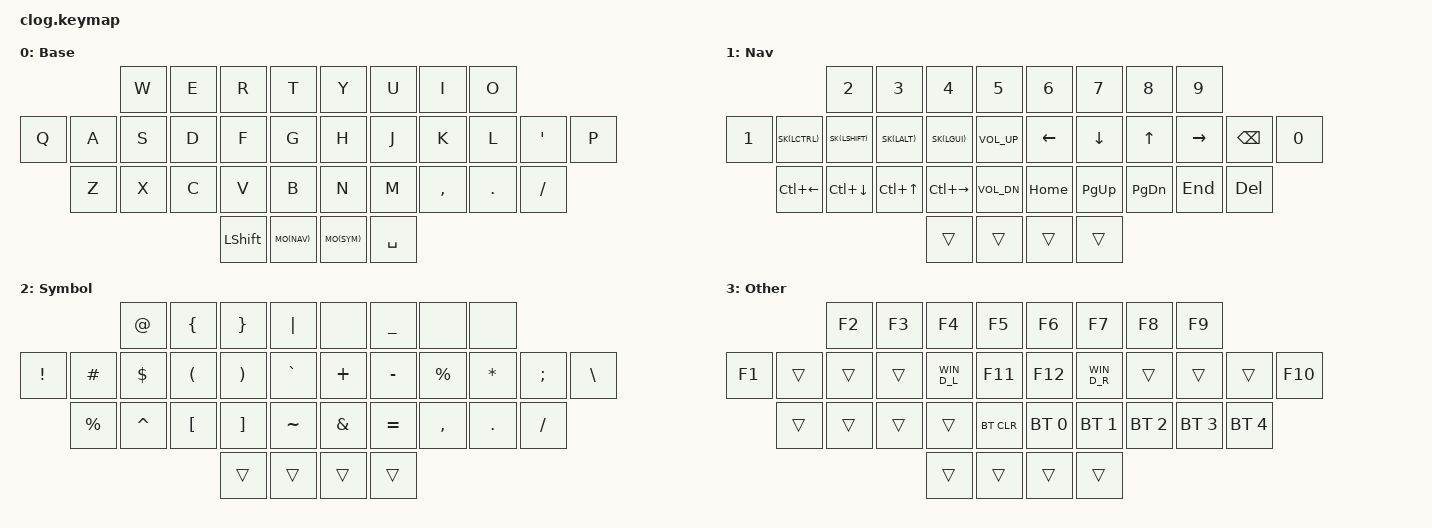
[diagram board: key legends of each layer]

/*
 * Copyright (c) 2021 The ZMK Contributors
 *
 * SPDX-License-Identifier: MIT
 */

#include <behaviors.dtsi>
#include <dt-bindings/zmk/keys.h>
#include <dt-bindings/zmk/bt.h>
#include <dt-bindings/zmk/outputs.h>

#define XXX &none
#define ___ &trans

#define WIN_D_L LC(LG(LEFT))
#define WIN_D_R LC(LG(RIGHT))

#define SK(KEY) &nk KEY KEY
#define MO(LAYER) &mo_tap LAYER F24

// Keep sticky keys active for a long time so they effectively do not time out
#define STICKY_KEY_TIMEOUT 60000

#define BASE 0
#define NAV 1
#define SYM 2
#define OTHER 3

&sk {
  release-after-ms = <STICKY_KEY_TIMEOUT>;
};

/ {
    combos {
        compatible = "zmk,combos";

/*              34-KEY POSITIONS

          ╭─────────────────╮ ╭──────────────────╮
  ╭───────╯  0   1   2   3  │ │   4   5   6   7  ╰──────╮
  │  8   9  10  11  12  13  │ │  14  15  16  17  18  19 │
  ╰───╮ 20  21  22  23  24  │ │  25  26  27  28  29 ╭───╯
      ╰──────────╮  30  31  │ │ 32  33 ╭────────────╯
                 ╰──────────╯ ╰────────╯            */


        escape {
            timeout-ms = <50>;
            key-positions = <8 12>;
            bindings = <&kp ESC>;
        };


        enter {
            timeout-ms = <50>;
            key-positions = <15 19>;
            bindings = <&kp ENTER>;
        };

        tab {
            timeout-ms = <50>;
            key-positions = <12 31>;
            bindings = <&kp TAB>;
        };

        untab {
            timeout-ms = <50>;
            key-positions = <15 32>;
            bindings = <&kp LS(TAB)>;
        };

    };

    behaviors {

      skq: sticky_key_quick_release {
        compatible = "zmk,behavior-sticky-key";
        label = "STICKY_KEY_QUICK_RELEASE";
        #binding-cells = <1>;
        bindings = <&kp>;
        quick-release;
        release-after-ms = <STICKY_KEY_TIMEOUT>;
      };

      // Use hold-tap to enable rolling sticky keys:
      // https://github.com/zmkfirmware/zmk/issues/829#issuecomment-979864774
      nk: not_so_sticky_key {
        compatible = "zmk,behavior-hold-tap";
        label = "NOT_SO_STICKY_KEY";
        #binding-cells = <2>;
        tapping_term_ms = <200>;
        flavor = "tap-preferred";
        bindings = <&kp>, <&sk>;
      };

      // A hold-tap that activates without delay (like `&mo`)
      mo_tap: mo_with_tap {
        compatible = "zmk,behavior-hold-tap";
        label = "MO_WITH_TAP";
        #binding-cells = <2>;
        tapping_term_ms = <0>;
        retro-tap;
        flavor = "hold-preferred";
        bindings = <&mo>, <&kp>;
      };

    };

    conditional_layers {
        compatible = "zmk,conditional-layers";
        tri_layer {
          if-layers = <NAV SYM>;
          then-layer= <OTHER>;
        };
    };

    keymap {
        compatible = "zmk,keymap";

        base_layer {
            label = "Base";
            bindings = <
        //                             ╭─────────────┬─────────────┬─────────────┬─────────────╮   ╭─────────────┬─────────────┬─────────────┬─────────────╮
                                         &kp W         &kp E         &kp R         &kp T             &kp Y         &kp U         &kp I         &kp O         
        // ╭─────────────┬─────────────┼─────────────┼─────────────┼─────────────┼─────────────┤   ├─────────────┼─────────────┼─────────────┼─────────────┼─────────────┬─────────────╮
             &kp Q         &kp A         &kp S         &kp D         &kp F         &kp G             &kp H         &kp J         &kp K         &kp L         &kp QUOT      &kp P         
        // ╰─────────────┼─────────────┼─────────────┼─────────────┼─────────────┼─────────────┤   ├─────────────┼─────────────┼─────────────┼─────────────┼─────────────┼─────────────╯
                           &kp Z         &kp X         &kp C         &kp V         &kp B             &kp N         &kp M         &kp COMMA     &kp DOT       &kp FSLH
        //               ╰─────────────┴─────────────┴─────────────┼─────────────┼─────────────┤   ├─────────────┼─────────────┼─────────────┴─────────────┴─────────────╯
                                                                     &kp LSHIFT    MO(NAV)           MO(SYM)       &kp SPACE     
        //                                                         ╰─────────────┴─────────────╯   ╰─────────────┴─────────────╯
            >;
        };

        nav_layer {
            label = "Nav";
            bindings = <
        //                             ╭─────────────┬─────────────┬─────────────┬─────────────╮   ╭─────────────┬─────────────┬─────────────┬─────────────╮
                                         &kp N2        &kp N3        &kp N4        &kp N5            &kp N6        &kp N7        &kp N8        &kp N9        
        // ╭─────────────┬─────────────┼─────────────┼─────────────┼─────────────┼─────────────┤   ├─────────────┼─────────────┼─────────────┼─────────────┼─────────────┬─────────────╮
             &kp N1        SK(LCTRL)     SK(LSHIFT)    SK(LALT)      SK(LGUI)      &kp C_VOL_UP      &kp LEFT      &kp DOWN      &kp UP        &kp RIGHT     &kp BSPC      &kp N0 
        // ╰─────────────┼─────────────┼─────────────┼─────────────┼─────────────┼─────────────┤   ├─────────────┼─────────────┼─────────────┼─────────────┼─────────────┼─────────────╯
                           &kp LC(LEFT)  &kp LC(DOWN)  &kp LC(UP)    &kp LC(RIGHT) &kp C_VOL_DN      &kp HOME      &kp PG_UP     &kp PG_DN     &kp END       &kp DEL
        //               ╰─────────────┴─────────────┴─────────────┼─────────────┼─────────────┤   ├─────────────┼─────────────┼─────────────┴─────────────┴─────────────╯
                                                                     ___           ___               ___           ___
        //                                                         ╰─────────────┴─────────────╯   ╰─────────────┴─────────────╯
            >;
        };

        sym_layer {
            label = "Symbol";
            bindings = <
        //                             ╭─────────────┬─────────────┬─────────────┬─────────────╮   ╭─────────────┬─────────────┬─────────────┬─────────────╮
                                         &kp AT        &kp LBRC      &kp RBRC      &kp PIPE          &none         &kp UNDER     &none         &none         
        // ╭─────────────┬─────────────┼─────────────┼─────────────┼─────────────┼─────────────┤   ├─────────────┼─────────────┼─────────────┼─────────────┼─────────────┬─────────────╮
             &kp EXCL      &kp HASH      &kp DOLLAR    &kp LPAR      &kp RPAR      &kp GRAVE         &kp PLUS      &kp MINUS     &kp PERCENT   &kp ASTRK     &kp SEMI      &kp BSLH
        // ╰─────────────┼─────────────┼─────────────┼─────────────┼─────────────┼─────────────┤   ├─────────────┼─────────────┼─────────────┼─────────────┼─────────────┼─────────────╯
                           &kp PERCENT   &kp CARET     &kp LBKT      &kp RBKT      &kp TILDE         &kp AMPS      &kp EQUAL     &kp COMMA     &kp DOT       &kp SLASH
        //               ╰─────────────┴─────────────┴─────────────┼─────────────┼─────────────┤   ├─────────────┼─────────────┼─────────────┴─────────────┴─────────────╯
                                                                     ___           ___               ___           ___
        //                                                         ╰─────────────┴─────────────╯   ╰─────────────┴─────────────╯
            >;
        };

        other_layer {
            label = "Other";
            bindings = <
        //                             ╭─────────────┬─────────────┬─────────────┬─────────────╮   ╭─────────────┬─────────────┬─────────────┬─────────────╮
                                	       &kp F2        &kp F3        &kp F4        &kp F5            &kp F6        &kp F7        &kp F8        &kp F9        
        // ╭─────────────┬─────────────┼─────────────┼─────────────┼─────────────┼─────────────┤   ├─────────────┼─────────────┼─────────────┼─────────────┼─────────────┬─────────────╮
             &kp F1        ___           ___           ___           &kp WIN_D_L   &kp F11           &kp F12       &kp WIN_D_R   ___           ___           ___           &kp F10
        // ╰─────────────┼─────────────┼─────────────┼─────────────┼─────────────┼─────────────┤   ├─────────────┼─────────────┼─────────────┼─────────────┼─────────────┼─────────────╯
                           ___           ___           ___           ___           &bt BT_CLR       &bt BT_SEL 0  &bt BT_SEL 1  &bt BT_SEL 2  &bt BT_SEL 3  &bt BT_SEL 4
        //               ╰─────────────┴─────────────┴─────────────┼─────────────┼─────────────┤   ├─────────────┼─────────────┼─────────────┴─────────────┴─────────────╯
                                                                     ___           ___               ___           ___
        //                                                         ╰─────────────┴─────────────╯   ╰─────────────┴─────────────╯
            >;
        };

    };
};
